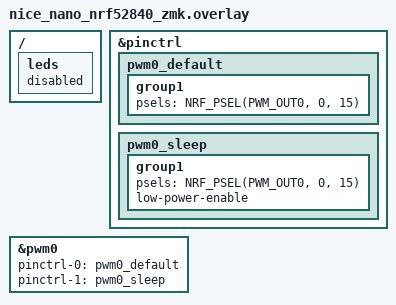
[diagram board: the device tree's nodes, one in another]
/*
 * Board-specific overlay for CyberFly on nice!nano (nRF52840)
 *
 * Backlight: P0.15 → AP3032 CTRL (PWM boost LED driver)
 * EXT_POWER and REG0 already configured by nice_nano v2 board overlay.
 */

&pinctrl {
    pwm0_default: pwm0_default {
        group1 {
            psels = <NRF_PSEL(PWM_OUT0, 0, 15)>;
        };
    };
    pwm0_sleep: pwm0_sleep {
        group1 {
            psels = <NRF_PSEL(PWM_OUT0, 0, 15)>;
            low-power-enable;
        };
    };
};

&pwm0 {
    status = "okay";
    pinctrl-0 = <&pwm0_default>;
    pinctrl-1 = <&pwm0_sleep>;
    pinctrl-names = "default", "sleep";
};

/* nice!nano defines P0.15 as blue_led (gpio-leds), but cyberfly uses it
 * for PWM backlight. Disable the gpio-leds node to avoid pin conflict. */
/ {
    leds {
        status = "disabled";
    };
};
